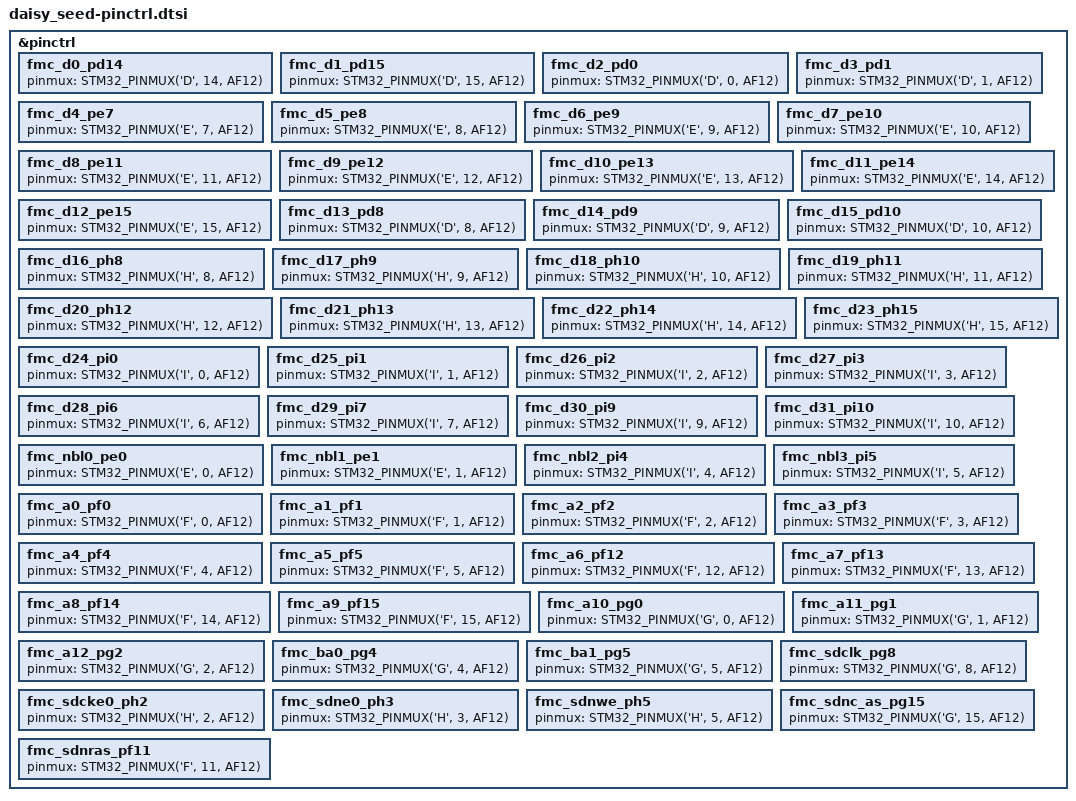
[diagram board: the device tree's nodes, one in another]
&pinctrl {
    // Data pins D0-D15 (Port D/E)
    fmc_d0_pd14: fmc_d0_pd14 {
        pinmux = <STM32_PINMUX('D', 14, AF12)>;
    };
    fmc_d1_pd15: fmc_d1_pd15 {
        pinmux = <STM32_PINMUX('D', 15, AF12)>;
    };
    fmc_d2_pd0: fmc_d2_pd0 {
        pinmux = <STM32_PINMUX('D', 0, AF12)>;
    };
    fmc_d3_pd1: fmc_d3_pd1 {
        pinmux = <STM32_PINMUX('D', 1, AF12)>;
    };
    fmc_d4_pe7: fmc_d4_pe7 {
        pinmux = <STM32_PINMUX('E', 7, AF12)>;
    };
    fmc_d5_pe8: fmc_d5_pe8 {
        pinmux = <STM32_PINMUX('E', 8, AF12)>;
    };
    fmc_d6_pe9: fmc_d6_pe9 {
        pinmux = <STM32_PINMUX('E', 9, AF12)>;
    };
    fmc_d7_pe10: fmc_d7_pe10 {
        pinmux = <STM32_PINMUX('E', 10, AF12)>;
    };
    fmc_d8_pe11: fmc_d8_pe11 {
        pinmux = <STM32_PINMUX('E', 11, AF12)>;
    };
    fmc_d9_pe12: fmc_d9_pe12 {
        pinmux = <STM32_PINMUX('E', 12, AF12)>;
    };
    fmc_d10_pe13: fmc_d10_pe13 {
        pinmux = <STM32_PINMUX('E', 13, AF12)>;
    };
    fmc_d11_pe14: fmc_d11_pe14 {
        pinmux = <STM32_PINMUX('E', 14, AF12)>;
    };
    fmc_d12_pe15: fmc_d12_pe15 {
        pinmux = <STM32_PINMUX('E', 15, AF12)>;
    };
    fmc_d13_pd8: fmc_d13_pd8 {
        pinmux = <STM32_PINMUX('D', 8, AF12)>;
    };
    fmc_d14_pd9: fmc_d14_pd9 {
        pinmux = <STM32_PINMUX('D', 9, AF12)>;
    };
    fmc_d15_pd10: fmc_d15_pd10 {
        pinmux = <STM32_PINMUX('D', 10, AF12)>;
    };

    // Data pins D16-D23 (Port H)
    fmc_d16_ph8: fmc_d16_ph8 {
        pinmux = <STM32_PINMUX('H', 8, AF12)>;
    };
    fmc_d17_ph9: fmc_d17_ph9 {
        pinmux = <STM32_PINMUX('H', 9, AF12)>;
    };
    fmc_d18_ph10: fmc_d18_ph10 {
        pinmux = <STM32_PINMUX('H', 10, AF12)>;
    };
    fmc_d19_ph11: fmc_d19_ph11 {
        pinmux = <STM32_PINMUX('H', 11, AF12)>;
    };
    fmc_d20_ph12: fmc_d20_ph12 {
        pinmux = <STM32_PINMUX('H', 12, AF12)>;
    };
    fmc_d21_ph13: fmc_d21_ph13 {
        pinmux = <STM32_PINMUX('H', 13, AF12)>;
    };
    fmc_d22_ph14: fmc_d22_ph14 {
        pinmux = <STM32_PINMUX('H', 14, AF12)>;
    };
    fmc_d23_ph15: fmc_d23_ph15 {
        pinmux = <STM32_PINMUX('H', 15, AF12)>;
    };

    // Data pins D24-D31 (Port I)
    fmc_d24_pi0: fmc_d24_pi0 {
        pinmux = <STM32_PINMUX('I', 0, AF12)>;
    };
    fmc_d25_pi1: fmc_d25_pi1 {
        pinmux = <STM32_PINMUX('I', 1, AF12)>;
    };
    fmc_d26_pi2: fmc_d26_pi2 {
        pinmux = <STM32_PINMUX('I', 2, AF12)>;
    };
    fmc_d27_pi3: fmc_d27_pi3 {
        pinmux = <STM32_PINMUX('I', 3, AF12)>;
    };
    fmc_d28_pi6: fmc_d28_pi6 {
        pinmux = <STM32_PINMUX('I', 6, AF12)>;
    };
    fmc_d29_pi7: fmc_d29_pi7 {
        pinmux = <STM32_PINMUX('I', 7, AF12)>;
    };
    fmc_d30_pi9: fmc_d30_pi9 {
        pinmux = <STM32_PINMUX('I', 9, AF12)>;
    };
    fmc_d31_pi10: fmc_d31_pi10 {
        pinmux = <STM32_PINMUX('I', 10, AF12)>;
    };

    // Byte lane signals
    fmc_nbl0_pe0: fmc_nbl0_pe0 {
        pinmux = <STM32_PINMUX('E', 0, AF12)>;
    };
    fmc_nbl1_pe1: fmc_nbl1_pe1 {
        pinmux = <STM32_PINMUX('E', 1, AF12)>;
    };
    fmc_nbl2_pi4: fmc_nbl2_pi4 {
        pinmux = <STM32_PINMUX('I', 4, AF12)>;
    };
    fmc_nbl3_pi5: fmc_nbl3_pi5 {
        pinmux = <STM32_PINMUX('I', 5, AF12)>;
    };

    // Address pins A0-A9 (Port F)
    fmc_a0_pf0: fmc_a0_pf0 {
        pinmux = <STM32_PINMUX('F', 0, AF12)>;
    };
    fmc_a1_pf1: fmc_a1_pf1 {
        pinmux = <STM32_PINMUX('F', 1, AF12)>;
    };
    fmc_a2_pf2: fmc_a2_pf2 {
        pinmux = <STM32_PINMUX('F', 2, AF12)>;
    };
    fmc_a3_pf3: fmc_a3_pf3 {
        pinmux = <STM32_PINMUX('F', 3, AF12)>;
    };
    fmc_a4_pf4: fmc_a4_pf4 {
        pinmux = <STM32_PINMUX('F', 4, AF12)>;
    };
    fmc_a5_pf5: fmc_a5_pf5 {
        pinmux = <STM32_PINMUX('F', 5, AF12)>;
    };
    fmc_a6_pf12: fmc_a6_pf12 {
        pinmux = <STM32_PINMUX('F', 12, AF12)>;
    };
    fmc_a7_pf13: fmc_a7_pf13 {
        pinmux = <STM32_PINMUX('F', 13, AF12)>;
    };
    fmc_a8_pf14: fmc_a8_pf14 {
        pinmux = <STM32_PINMUX('F', 14, AF12)>;
    };
    fmc_a9_pf15: fmc_a9_pf15 {
        pinmux = <STM32_PINMUX('F', 15, AF12)>;
    };

    // Address pins A10-A12 (Port G)
    fmc_a10_pg0: fmc_a10_pg0 {
        pinmux = <STM32_PINMUX('G', 0, AF12)>;
    };
    fmc_a11_pg1: fmc_a11_pg1 {
        pinmux = <STM32_PINMUX('G', 1, AF12)>;
    };
    fmc_a12_pg2: fmc_a12_pg2 {
        pinmux = <STM32_PINMUX('G', 2, AF12)>;
    };

    // Bank address pins (Port G)
    fmc_ba0_pg4: fmc_ba0_pg4 {
        pinmux = <STM32_PINMUX('G', 4, AF12)>;
    };
    fmc_ba1_pg5: fmc_ba1_pg5 {
        pinmux = <STM32_PINMUX('G', 5, AF12)>;
    };

    // Control signals
    fmc_sdclk_pg8: fmc_sdclk_pg8 {
        pinmux = <STM32_PINMUX('G', 8, AF12)>;
    };
    fmc_sdcke0_ph2: fmc_sdcke0_ph2 {
        pinmux = <STM32_PINMUX('H', 2, AF12)>;
    };
    fmc_sdne0_ph3: fmc_sdne0_ph3 {
        pinmux = <STM32_PINMUX('H', 3, AF12)>;
    };
    fmc_sdnwe_ph5: fmc_sdnwe_ph5 {
        pinmux = <STM32_PINMUX('H', 5, AF12)>;
    };
    fmc_sdnc_as_pg15: fmc_sdnc_as_pg15 {
        pinmux = <STM32_PINMUX('G', 15, AF12)>;
    };
    fmc_sdnras_pf11: fmc_sdnras_pf11 {
        pinmux = <STM32_PINMUX('F', 11, AF12)>;
    };
};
